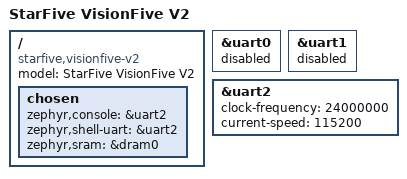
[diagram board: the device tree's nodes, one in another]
/*
 * Copyright (c) 2024 Kanak Shilledar <kanakshilledar111@protonmail.com>
 *
 * SPDX-License-Identifier: Apache-2.0
 */

/dts-v1/;

#include "starfive/jh7110-visionfive-v2.dtsi"

/ {
	model = "StarFive VisionFive V2";
	compatible = "starfive,visionfive-v2";

	chosen {
		zephyr,console = &uart2;
		zephyr,shell-uart = &uart2;
		zephyr,sram = &dram0;
	};
};

&uart0 {
	status = "disabled";
};

&uart1 {
	status = "disabled";
};

&uart2 {
	status = "okay";
	clock-frequency = <24000000>;
	current-speed = <115200>;
};
